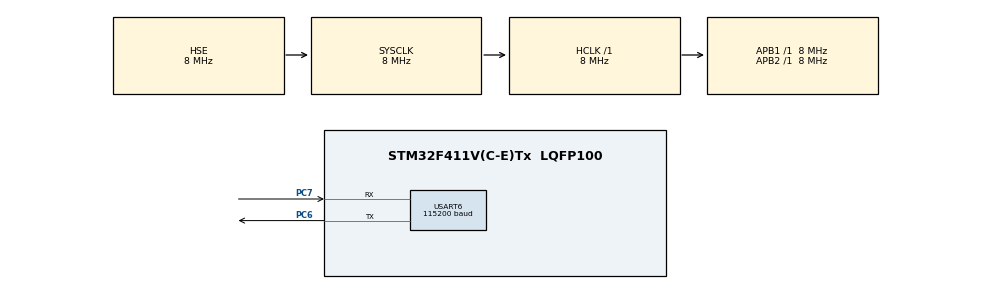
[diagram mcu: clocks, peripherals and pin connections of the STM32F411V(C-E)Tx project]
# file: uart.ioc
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Mcu.Family=STM32F4
Mcu.Name=STM32F411V(C-E)Tx
Mcu.Package=LQFP100
NVIC.PriorityGroup=NVIC_PRIORITYGROUP_4
NVIC.USART6_IRQn=true\:0\:0\:false\:false\:true\:true\:true\:true
PA13.Mode=Serial_Wire
PA13.Signal=SYS_JTMS-SWDIO
PA14.Mode=Serial_Wire
PA14.Signal=SYS_JTCK-SWCLK
PC6.Mode=Asynchronous
PC6.Signal=USART6_TX
PC7.Mode=Asynchronous
PC7.Signal=USART6_RX
PH0\ -\ OSC_IN.Mode=HSE-External-Oscillator
PH0\ -\ OSC_IN.Signal=RCC_OSC_IN
PH1\ -\ OSC_OUT.Mode=HSE-External-Oscillator
PH1\ -\ OSC_OUT.Signal=RCC_OSC_OUT
ProjectManager.HeapSize=0x200
ProjectManager.StackSize=0x400
ProjectManager.TargetToolchain=STM32CubeIDE
RCC.AHBFreq_Value=8000000
RCC.APB1Freq_Value=8000000
RCC.APB1TimFreq_Value=8000000
RCC.APB2Freq_Value=8000000
RCC.APB2TimFreq_Value=8000000
RCC.CortexFreq_Value=8000000
RCC.HCLKFreq_Value=8000000
RCC.HSE_VALUE=8000000
RCC.HSI_VALUE=16000000
RCC.LSE_VALUE=32768
RCC.SYSCLKFreq_VALUE=8000000
RCC.SYSCLKSource=RCC_SYSCLKSOURCE_HSE
RCC.VCOOutputFreq_Value=192000000
USART6.BaudRate=115200
USART6.VirtualMode=VM_ASYNC
board=custom

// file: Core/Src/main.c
/* USER CODE BEGIN Header */
/**
  ******************************************************************************
  * @file           : main.c
  * @brief          : Main program body
  ******************************************************************************
  * @attention
  *
  * Copyright (c) 2022 STMicroelectronics.
  * All rights reserved.
  *
  * This software is licensed under terms that can be found in the LICENSE file
  * in the root directory of this software component.
  * If no LICENSE file comes with this software, it is provided AS-IS.
  *
  ******************************************************************************
  */
/* USER CODE END Header */
#include "main.h"

 UART_HandleTypeDef huart6;

/* USER CODE BEGIN PV */
 char Rx_data[11] = { 0 };
/* USER CODE END PV */

void SystemClock_Config(void);
static void MX_GPIO_Init(void);
static void MX_USART6_UART_Init(void);
/* USER CODE BEGIN PFP */
uint8_t senddata[]="LED1ON";
char rec,null;
char buffer[100];
int i=0;
char chuoiA[3],chuoiB[3];
char EU[] = "EUM",US[] = "US";
uint8_t f,v=1;
uint8_t e = 0;  ///
/* USER CODE END PFP */

/* USER CODE BEGIN 0 */
void HAL_UART_RxCpltCallback(UART_HandleTypeDef *huart)
{
	if(huart->Instance == huart6.Instance ){
		if(rec!=13)
			{
			buffer[i++]=rec; // 13 = /r
			e = 0;  ///
			}
		else if(rec==13)
			{
				i=0;
				// new
					uint8_t TimA, TimB, TimC ;
					for(int j=0; j < sizeof(buffer); j++)
					{
						if(buffer[j] == 'a')
						{
							TimA = j;
						}
						if(buffer[j] == 'b')
						{
							TimB = j;
						}
						if(buffer[j] == 'c')
						{
							TimC = j;
						}
					}
					if(TimA >=0 && TimB >0 && TimC >0)
						{
							int c = 0 ;
							for(int j = TimA; j < TimB - 1; j++){

								chuoiA[c] = buffer[j+1];
								c++;
							}

							c = 0;
							for(int j = TimB; j < TimC -1; j++)
							{

								chuoiB[c] = buffer[j+1];
								c++;
							}
							/* execute compare char of 2 array then control everything you want
							 * */
							 for(int a = 0; a < sizeof(chuoiA); a++){
								 if(chuoiA[a] == EU[a]){
									 f = 1;
								 }
								 else f=0;
							 }
							 for(int a = 0; a < sizeof(chuoiB); a++){
								 if(chuoiB[a] == US[a]){
									 v = 0;
								 }
								 else v=1;
							 }
						}

				for(int cnt=0; cnt < sizeof(buffer);cnt++)
					{
					buffer[cnt]=null;

					}
			}
		/*
			if(sizeof(buffer) == 0){
				HAL_UART_Transmit(&huart6,(uint8_t *)&senddata, sizeof(senddata),100);
			}*/
				HAL_UART_Receive_IT(&huart6,(uint8_t *)&rec,1);/* khai bao de lan sau ngat tiep */

	}
}
/* USER CODE END 0 */

int main(void)
{

  /* MCU Configuration--------------------------------------------------------*/

  /* Reset of all peripherals, Initializes the Flash interface and the Systick. */
  HAL_Init();

  /* Configure the system clock */
  SystemClock_Config();

  /* Initialize all configured peripherals */
  MX_GPIO_Init();
  MX_USART6_UART_Init();
  /* USER CODE BEGIN 2 */

	HAL_UART_Receive_IT(&huart6,(uint8_t *)&rec,1);
  /* USER CODE END 2 */

  /* Infinite loop */
  /* USER CODE BEGIN WHILE */
  while (1)
  {
	 HAL_UART_Transmit(&huart6, senddata,sizeof(senddata),100);
	  HAL_Delay(10000);

    /* USER CODE END WHILE */

  }
}

void SystemClock_Config(void)
{
  RCC_OscInitTypeDef RCC_OscInitStruct = {0};
  RCC_ClkInitTypeDef RCC_ClkInitStruct = {0};

  /** Configure the main internal regulator output voltage
  */
  __HAL_RCC_PWR_CLK_ENABLE();
  __HAL_PWR_VOLTAGESCALING_CONFIG(PWR_REGULATOR_VOLTAGE_SCALE1);

  /** Initializes the RCC Oscillators according to the specified parameters
  * in the RCC_OscInitTypeDef structure.
  */
  RCC_OscInitStruct.OscillatorType = RCC_OSCILLATORTYPE_HSE;
  RCC_OscInitStruct.HSEState = RCC_HSE_ON;
  RCC_OscInitStruct.PLL.PLLState = RCC_PLL_NONE;
  if (HAL_RCC_OscConfig(&RCC_OscInitStruct) != HAL_OK)
  {
    Error_Handler();
  }

  /** Initializes the CPU, AHB and APB buses clocks
  */
  RCC_ClkInitStruct.ClockType = RCC_CLOCKTYPE_HCLK|RCC_CLOCKTYPE_SYSCLK
                              |RCC_CLOCKTYPE_PCLK1|RCC_CLOCKTYPE_PCLK2;
  RCC_ClkInitStruct.SYSCLKSource = RCC_SYSCLKSOURCE_HSE;
  RCC_ClkInitStruct.AHBCLKDivider = RCC_SYSCLK_DIV1;
  RCC_ClkInitStruct.APB1CLKDivider = RCC_HCLK_DIV1;
  RCC_ClkInitStruct.APB2CLKDivider = RCC_HCLK_DIV1;

  if (HAL_RCC_ClockConfig(&RCC_ClkInitStruct, FLASH_LATENCY_0) != HAL_OK)
  {
    Error_Handler();
  }
}

static void MX_USART6_UART_Init(void)
{

  huart6.Instance = USART6;
  huart6.Init.BaudRate = 115200;
  huart6.Init.WordLength = UART_WORDLENGTH_8B;
  huart6.Init.StopBits = UART_STOPBITS_1;
  huart6.Init.Parity = UART_PARITY_NONE;
  huart6.Init.Mode = UART_MODE_TX_RX;
  huart6.Init.HwFlowCtl = UART_HWCONTROL_NONE;
  huart6.Init.OverSampling = UART_OVERSAMPLING_16;
  if (HAL_UART_Init(&huart6) != HAL_OK)
  {
    Error_Handler();
  }

}

static void MX_GPIO_Init(void)
{

  /* GPIO Ports Clock Enable */
  __HAL_RCC_GPIOH_CLK_ENABLE();
  __HAL_RCC_GPIOC_CLK_ENABLE();
  __HAL_RCC_GPIOA_CLK_ENABLE();

}

void Error_Handler(void)
{
  __disable_irq();
  while (1)
  {
  }
}
